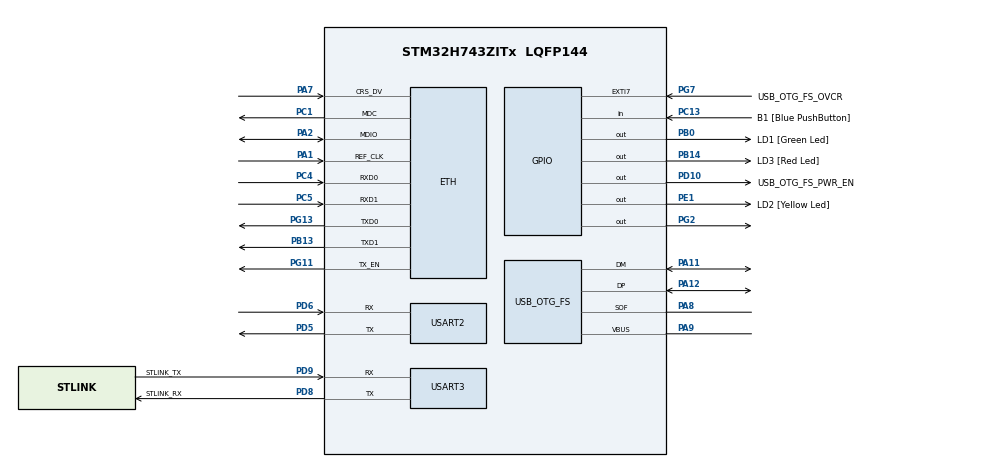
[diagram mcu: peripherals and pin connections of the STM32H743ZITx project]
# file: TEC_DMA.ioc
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Dma.Request0=USART2_RX
Dma.Request1=USART2_TX
Dma.USART2_RX.0.Direction=DMA_PERIPH_TO_MEMORY
Dma.USART2_RX.0.EventEnable=DISABLE
Dma.USART2_RX.0.FIFOMode=DMA_FIFOMODE_DISABLE
Dma.USART2_RX.0.Instance=DMA1_Stream0
Dma.USART2_RX.0.MemDataAlignment=DMA_MDATAALIGN_BYTE
Dma.USART2_RX.0.MemInc=DMA_MINC_ENABLE
Dma.USART2_RX.0.Mode=DMA_NORMAL
Dma.USART2_RX.0.PeriphDataAlignment=DMA_PDATAALIGN_BYTE
Dma.USART2_RX.0.PeriphInc=DMA_PINC_DISABLE
Dma.USART2_RX.0.Polarity=HAL_DMAMUX_REQ_GEN_RISING
Dma.USART2_RX.0.Priority=DMA_PRIORITY_LOW
Dma.USART2_RX.0.RequestNumber=1
Dma.USART2_RX.0.SignalID=NONE
Dma.USART2_RX.0.SyncEnable=DISABLE
Dma.USART2_RX.0.SyncPolarity=HAL_DMAMUX_SYNC_NO_EVENT
Dma.USART2_RX.0.SyncRequestNumber=1
Dma.USART2_RX.0.SyncSignalID=NONE
Dma.USART2_TX.1.Direction=DMA_MEMORY_TO_PERIPH
Dma.USART2_TX.1.EventEnable=DISABLE
Dma.USART2_TX.1.FIFOMode=DMA_FIFOMODE_DISABLE
Dma.USART2_TX.1.Instance=DMA1_Stream1
Dma.USART2_TX.1.MemDataAlignment=DMA_MDATAALIGN_BYTE
Dma.USART2_TX.1.MemInc=DMA_MINC_ENABLE
Dma.USART2_TX.1.Mode=DMA_NORMAL
Dma.USART2_TX.1.PeriphDataAlignment=DMA_PDATAALIGN_BYTE
Dma.USART2_TX.1.PeriphInc=DMA_PINC_DISABLE
Dma.USART2_TX.1.Polarity=HAL_DMAMUX_REQ_GEN_RISING
Dma.USART2_TX.1.Priority=DMA_PRIORITY_LOW
Dma.USART2_TX.1.RequestNumber=1
Dma.USART2_TX.1.SignalID=NONE
Dma.USART2_TX.1.SyncEnable=DISABLE
Dma.USART2_TX.1.SyncPolarity=HAL_DMAMUX_SYNC_NO_EVENT
Dma.USART2_TX.1.SyncRequestNumber=1
Dma.USART2_TX.1.SyncSignalID=NONE
ETH.MediaInterface=HAL_ETH_RMII_MODE
Mcu.Family=STM32H7
Mcu.Name=STM32H743ZITx
Mcu.Package=LQFP144
NVIC.DMA1_Stream0_IRQn=true\:0\:0\:false\:false\:true\:false\:true\:true
NVIC.DMA1_Stream1_IRQn=true\:0\:0\:false\:false\:true\:false\:true\:true
NVIC.PriorityGroup=NVIC_PRIORITYGROUP_4
NVIC.USART2_IRQn=true\:0\:0\:false\:false\:true\:true\:true\:true
PA1.Mode=RMII
PA1.Signal=ETH_REF_CLK
PA11.Mode=Device_Only
PA11.Signal=USB_OTG_FS_DM
PA12.Mode=Device_Only
PA12.Signal=USB_OTG_FS_DP
PA2.Mode=RMII
PA2.Signal=ETH_MDIO
PA7.Mode=RMII
PA7.Signal=ETH_CRS_DV
PA8.Mode=Activate_SOF_FS
PA8.Signal=USB_OTG_FS_SOF
PA9.Mode=Activate_VBUS
PA9.Signal=USB_OTG_FS_VBUS
PB0.GPIO_Label=LD1 [Green Led]
PB0.Signal=GPIO_Output
PB13.Mode=RMII
PB13.Signal=ETH_TXD1
PB14.GPIO_Label=LD3 [Red Led]
PB14.Signal=GPIO_Output
PC1.Mode=RMII
PC1.Signal=ETH_MDC
PC13.GPIO_Label=B1 [Blue PushButton]
PC13.Signal=GPIO_Input
PC14-OSC32_IN\ (OSC32_IN).Mode=LSE-External-Oscillator
PC14-OSC32_IN\ (OSC32_IN).Signal=RCC_OSC32_IN
PC15-OSC32_OUT\ (OSC32_OUT).Mode=LSE-External-Oscillator
PC15-OSC32_OUT\ (OSC32_OUT).Signal=RCC_OSC32_OUT
PC4.Mode=RMII
PC4.Signal=ETH_RXD0
PC5.Mode=RMII
PC5.Signal=ETH_RXD1
PD10.GPIO_Label=USB_OTG_FS_PWR_EN
PD10.Signal=GPIO_Output
PD5.Mode=Asynchronous
PD5.Signal=USART2_TX
PD6.Mode=Asynchronous
PD6.Signal=USART2_RX
PD8.GPIO_Label=STLINK_RX
PD8.Mode=Asynchronous
PD8.Signal=USART3_TX
PD9.GPIO_Label=STLINK_TX
PD9.Mode=Asynchronous
PD9.Signal=USART3_RX
PE1.GPIO_Label=LD2 [Yellow Led]
PE1.Signal=GPIO_Output
PG11.Mode=RMII
PG11.Signal=ETH_TX_EN
PG13.Mode=RMII
PG13.Signal=ETH_TXD0
PG2.Signal=GPIO_Output
PG7.GPIO_Label=USB_OTG_FS_OVCR
PG7.Signal=GPXTI7
PH0-OSC_IN\ (PH0).Mode=HSE-External-Clock-Source
PH0-OSC_IN\ (PH0).Signal=RCC_OSC_IN
PH1-OSC_OUT\ (PH1).Signal=RCC_OSC_OUT
ProjectManager.HeapSize=0x200
ProjectManager.StackSize=0x400
ProjectManager.TargetToolchain=STM32CubeIDE
RCC.ADCFreq_Value=16125000
RCC.APB1Freq_Value=100000000
RCC.APB2Freq_Value=100000000
RCC.APB3Freq_Value=100000000
RCC.APB4Freq_Value=100000000
RCC.CortexFreq_Value=400000000
RCC.D1PPRE=RCC_APB3_DIV2
RCC.D2PPRE1=RCC_APB1_DIV2
RCC.D2PPRE2=RCC_APB2_DIV2
RCC.D3PPRE=RCC_APB4_DIV2
RCC.DIVM1=1
RCC.DIVN1=100
RCC.DIVQ1=13
RCC.HCLKFreq_Value=200000000
RCC.HPRE=RCC_HCLK_DIV2
RCC.HSE_VALUE=8000000
RCC.PLL2FRACN=0
RCC.PLL3FRACN=0
RCC.PLLFRACN=0
RCC.PWR_Regulator_Voltage_Scale=PWR_REGULATOR_VOLTAGE_SCALE0
RCC.SYSCLKFreq_VALUE=400000000
RCC.SYSCLKSource=RCC_SYSCLKSOURCE_PLLCLK
RCC.USBFreq_Value=61538461.538461536
USART2.VirtualMode-Asynchronous=VM_ASYNC
USART3.VirtualMode-Asynchronous=VM_ASYNC
USB_OTG_FS.VirtualMode=Device_Only
board=NUCLEO-H743ZI2

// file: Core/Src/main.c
/* USER CODE BEGIN Header */
/**
  ******************************************************************************
  * @file           : main.c
  * @brief          : Main program body
  ******************************************************************************
  * @attention
  *
  * Copyright (c) 2024 STMicroelectronics.
  * All rights reserved.
  *
  * This software is licensed under terms that can be found in the LICENSE file
  * in the root directory of this software component.
  * If no LICENSE file comes with this software, it is provided AS-IS.
  *
  ******************************************************************************
  */
/* USER CODE END Header */
#include "main.h"
#include "string.h"

/* USER CODE BEGIN Includes */
#include "MTD1020T.h"
/* USER CODE END Includes */

#if defined ( __ICCARM__ ) /*!< IAR Compiler */
#pragma location=0x30000000
ETH_DMADescTypeDef  DMARxDscrTab[ETH_RX_DESC_CNT]; /* Ethernet Rx DMA Descriptors */
#pragma location=0x30000200
ETH_DMADescTypeDef  DMATxDscrTab[ETH_TX_DESC_CNT]; /* Ethernet Tx DMA Descriptors */

#elif defined ( __CC_ARM )  /* MDK ARM Compiler */

__attribute__((at(0x30000000))) ETH_DMADescTypeDef  DMARxDscrTab[ETH_RX_DESC_CNT]; /* Ethernet Rx DMA Descriptors */
__attribute__((at(0x30000200))) ETH_DMADescTypeDef  DMATxDscrTab[ETH_TX_DESC_CNT]; /* Ethernet Tx DMA Descriptors */

#elif defined ( __GNUC__ ) /* GNU Compiler */
ETH_DMADescTypeDef DMARxDscrTab[ETH_RX_DESC_CNT] __attribute__((section(".RxDecripSection"))); /* Ethernet Rx DMA Descriptors */
ETH_DMADescTypeDef DMATxDscrTab[ETH_TX_DESC_CNT] __attribute__((section(".TxDecripSection")));   /* Ethernet Tx DMA Descriptors */

#endif

ETH_TxPacketConfig TxConfig;

ETH_HandleTypeDef heth;

UART_HandleTypeDef huart2;
UART_HandleTypeDef huart3;
DMA_HandleTypeDef hdma_usart2_rx;
DMA_HandleTypeDef hdma_usart2_tx;

PCD_HandleTypeDef hpcd_USB_OTG_FS;

/* USER CODE BEGIN PV */

uint8_t rx[15];
uint8_t rx2[15];
/* USER CODE END PV */

void SystemClock_Config(void);
static void MX_GPIO_Init(void);
static void MX_DMA_Init(void);
static void MX_USART3_UART_Init(void);
static void MX_USB_OTG_FS_PCD_Init(void);
static void MX_USART2_UART_Init(void);
static void MX_ETH_Init(void);

int main(void)
{

  /* MCU Configuration--------------------------------------------------------*/

  /* Reset of all peripherals, Initializes the Flash interface and the Systick. */
  HAL_Init();

  /* Configure the system clock */
  SystemClock_Config();

  /* Initialize all configured peripherals */
  MX_GPIO_Init();
  MX_DMA_Init();
  MX_USART3_UART_Init();
  MX_USB_OTG_FS_PCD_Init();
  MX_USART2_UART_Init();
  MX_ETH_Init();
  /* USER CODE BEGIN 2 */
  MTD_Init();
 //TEC TEC;
  /* USER CODE END 2 */

  /* Infinite loop */
  /* USER CODE BEGIN WHILE */
  while (1)
  {
	//  HAL_UART_Transmit_DMA(&huart2, r_actual_T,4);
	  MTD_r_ActualTemp(rx2 );

	  //HAL_UARTEx_ReceiveToIdle_DMA(&huart2, rx, 10);

    /* USER CODE END WHILE */

  }
}

void SystemClock_Config(void)
{
  RCC_OscInitTypeDef RCC_OscInitStruct = {0};
  RCC_ClkInitTypeDef RCC_ClkInitStruct = {0};

  /** Supply configuration update enable
  */
  HAL_PWREx_ConfigSupply(PWR_LDO_SUPPLY);

  /** Configure the main internal regulator output voltage
  */
  __HAL_PWR_VOLTAGESCALING_CONFIG(PWR_REGULATOR_VOLTAGE_SCALE1);

  while(!__HAL_PWR_GET_FLAG(PWR_FLAG_VOSRDY)) {}

  __HAL_RCC_SYSCFG_CLK_ENABLE();
  __HAL_PWR_VOLTAGESCALING_CONFIG(PWR_REGULATOR_VOLTAGE_SCALE0);

  while(!__HAL_PWR_GET_FLAG(PWR_FLAG_VOSRDY)) {}

  /** Initializes the RCC Oscillators according to the specified parameters
  * in the RCC_OscInitTypeDef structure.
  */
  RCC_OscInitStruct.OscillatorType = RCC_OSCILLATORTYPE_HSE;
  RCC_OscInitStruct.HSEState = RCC_HSE_BYPASS;
  RCC_OscInitStruct.PLL.PLLState = RCC_PLL_ON;
  RCC_OscInitStruct.PLL.PLLSource = RCC_PLLSOURCE_HSE;
  RCC_OscInitStruct.PLL.PLLM = 1;
  RCC_OscInitStruct.PLL.PLLN = 100;
  RCC_OscInitStruct.PLL.PLLP = 2;
  RCC_OscInitStruct.PLL.PLLQ = 13;
  RCC_OscInitStruct.PLL.PLLR = 2;
  RCC_OscInitStruct.PLL.PLLRGE = RCC_PLL1VCIRANGE_3;
  RCC_OscInitStruct.PLL.PLLVCOSEL = RCC_PLL1VCOWIDE;
  RCC_OscInitStruct.PLL.PLLFRACN = 0;
  if (HAL_RCC_OscConfig(&RCC_OscInitStruct) != HAL_OK)
  {
    Error_Handler();
  }

  /** Initializes the CPU, AHB and APB buses clocks
  */
  RCC_ClkInitStruct.ClockType = RCC_CLOCKTYPE_HCLK|RCC_CLOCKTYPE_SYSCLK
                              |RCC_CLOCKTYPE_PCLK1|RCC_CLOCKTYPE_PCLK2
                              |RCC_CLOCKTYPE_D3PCLK1|RCC_CLOCKTYPE_D1PCLK1;
  RCC_ClkInitStruct.SYSCLKSource = RCC_SYSCLKSOURCE_PLLCLK;
  RCC_ClkInitStruct.SYSCLKDivider = RCC_SYSCLK_DIV1;
  RCC_ClkInitStruct.AHBCLKDivider = RCC_HCLK_DIV2;
  RCC_ClkInitStruct.APB3CLKDivider = RCC_APB3_DIV2;
  RCC_ClkInitStruct.APB1CLKDivider = RCC_APB1_DIV2;
  RCC_ClkInitStruct.APB2CLKDivider = RCC_APB2_DIV2;
  RCC_ClkInitStruct.APB4CLKDivider = RCC_APB4_DIV2;

  if (HAL_RCC_ClockConfig(&RCC_ClkInitStruct, FLASH_LATENCY_2) != HAL_OK)
  {
    Error_Handler();
  }
}

static void MX_ETH_Init(void)
{

   static uint8_t MACAddr[6];

  heth.Instance = ETH;
  MACAddr[0] = 0x00;
  MACAddr[1] = 0x80;
  MACAddr[2] = 0xE1;
  MACAddr[3] = 0x00;
  MACAddr[4] = 0x00;
  MACAddr[5] = 0x00;
  heth.Init.MACAddr = &MACAddr[0];
  heth.Init.MediaInterface = HAL_ETH_RMII_MODE;
  heth.Init.TxDesc = DMATxDscrTab;
  heth.Init.RxDesc = DMARxDscrTab;
  heth.Init.RxBuffLen = 1524;

  if (HAL_ETH_Init(&heth) != HAL_OK)
  {
    Error_Handler();
  }

  memset(&TxConfig, 0 , sizeof(ETH_TxPacketConfig));
  TxConfig.Attributes = ETH_TX_PACKETS_FEATURES_CSUM | ETH_TX_PACKETS_FEATURES_CRCPAD;
  TxConfig.ChecksumCtrl = ETH_CHECKSUM_IPHDR_PAYLOAD_INSERT_PHDR_CALC;
  TxConfig.CRCPadCtrl = ETH_CRC_PAD_INSERT;

}

static void MX_USART2_UART_Init(void)
{

  huart2.Instance = USART2;
  huart2.Init.BaudRate = 115200;
  huart2.Init.WordLength = UART_WORDLENGTH_8B;
  huart2.Init.StopBits = UART_STOPBITS_1;
  huart2.Init.Parity = UART_PARITY_NONE;
  huart2.Init.Mode = UART_MODE_TX_RX;
  huart2.Init.HwFlowCtl = UART_HWCONTROL_NONE;
  huart2.Init.OverSampling = UART_OVERSAMPLING_16;
  huart2.Init.OneBitSampling = UART_ONE_BIT_SAMPLE_DISABLE;
  huart2.Init.ClockPrescaler = UART_PRESCALER_DIV1;
  huart2.AdvancedInit.AdvFeatureInit = UART_ADVFEATURE_NO_INIT;
  if (HAL_UART_Init(&huart2) != HAL_OK)
  {
    Error_Handler();
  }
  if (HAL_UARTEx_SetTxFifoThreshold(&huart2, UART_TXFIFO_THRESHOLD_1_8) != HAL_OK)
  {
    Error_Handler();
  }
  if (HAL_UARTEx_SetRxFifoThreshold(&huart2, UART_RXFIFO_THRESHOLD_1_8) != HAL_OK)
  {
    Error_Handler();
  }
  if (HAL_UARTEx_DisableFifoMode(&huart2) != HAL_OK)
  {
    Error_Handler();
  }

}

static void MX_USART3_UART_Init(void)
{

  huart3.Instance = USART3;
  huart3.Init.BaudRate = 115200;
  huart3.Init.WordLength = UART_WORDLENGTH_8B;
  huart3.Init.StopBits = UART_STOPBITS_1;
  huart3.Init.Parity = UART_PARITY_NONE;
  huart3.Init.Mode = UART_MODE_TX_RX;
  huart3.Init.HwFlowCtl = UART_HWCONTROL_NONE;
  huart3.Init.OverSampling = UART_OVERSAMPLING_16;
  huart3.Init.OneBitSampling = UART_ONE_BIT_SAMPLE_DISABLE;
  huart3.Init.ClockPrescaler = UART_PRESCALER_DIV1;
  huart3.AdvancedInit.AdvFeatureInit = UART_ADVFEATURE_NO_INIT;
  if (HAL_UART_Init(&huart3) != HAL_OK)
  {
    Error_Handler();
  }
  if (HAL_UARTEx_SetTxFifoThreshold(&huart3, UART_TXFIFO_THRESHOLD_1_8) != HAL_OK)
  {
    Error_Handler();
  }
  if (HAL_UARTEx_SetRxFifoThreshold(&huart3, UART_RXFIFO_THRESHOLD_1_8) != HAL_OK)
  {
    Error_Handler();
  }
  if (HAL_UARTEx_DisableFifoMode(&huart3) != HAL_OK)
  {
    Error_Handler();
  }

}

static void MX_USB_OTG_FS_PCD_Init(void)
{

  hpcd_USB_OTG_FS.Instance = USB_OTG_FS;
  hpcd_USB_OTG_FS.Init.dev_endpoints = 9;
  hpcd_USB_OTG_FS.Init.speed = PCD_SPEED_FULL;
  hpcd_USB_OTG_FS.Init.dma_enable = DISABLE;
  hpcd_USB_OTG_FS.Init.phy_itface = PCD_PHY_EMBEDDED;
  hpcd_USB_OTG_FS.Init.Sof_enable = ENABLE;
  hpcd_USB_OTG_FS.Init.low_power_enable = DISABLE;
  hpcd_USB_OTG_FS.Init.lpm_enable = DISABLE;
  hpcd_USB_OTG_FS.Init.battery_charging_enable = ENABLE;
  hpcd_USB_OTG_FS.Init.vbus_sensing_enable = ENABLE;
  hpcd_USB_OTG_FS.Init.use_dedicated_ep1 = DISABLE;
  if (HAL_PCD_Init(&hpcd_USB_OTG_FS) != HAL_OK)
  {
    Error_Handler();
  }

}

static void MX_DMA_Init(void)
{

  /* DMA controller clock enable */
  __HAL_RCC_DMA1_CLK_ENABLE();

  /* DMA interrupt init */
  /* DMA1_Stream0_IRQn interrupt configuration */
  HAL_NVIC_SetPriority(DMA1_Stream0_IRQn, 0, 0);
  HAL_NVIC_EnableIRQ(DMA1_Stream0_IRQn);
  /* DMA1_Stream1_IRQn interrupt configuration */
  HAL_NVIC_SetPriority(DMA1_Stream1_IRQn, 0, 0);
  HAL_NVIC_EnableIRQ(DMA1_Stream1_IRQn);

}

static void MX_GPIO_Init(void)
{
  GPIO_InitTypeDef GPIO_InitStruct = {0};

  /* GPIO Ports Clock Enable */
  __HAL_RCC_GPIOC_CLK_ENABLE();
  __HAL_RCC_GPIOH_CLK_ENABLE();
  __HAL_RCC_GPIOA_CLK_ENABLE();
  __HAL_RCC_GPIOB_CLK_ENABLE();
  __HAL_RCC_GPIOD_CLK_ENABLE();
  __HAL_RCC_GPIOG_CLK_ENABLE();
  __HAL_RCC_GPIOE_CLK_ENABLE();

  /*Configure GPIO pin Output Level */
  HAL_GPIO_WritePin(GPIOB, LD1_Pin|LD3_Pin, GPIO_PIN_RESET);

  /*Configure GPIO pin Output Level */
  HAL_GPIO_WritePin(USB_OTG_FS_PWR_EN_GPIO_Port, USB_OTG_FS_PWR_EN_Pin, GPIO_PIN_RESET);

  /*Configure GPIO pin Output Level */
  HAL_GPIO_WritePin(GPIOG, GPIO_PIN_2, GPIO_PIN_RESET);

  /*Configure GPIO pin Output Level */
  HAL_GPIO_WritePin(LD2_GPIO_Port, LD2_Pin, GPIO_PIN_RESET);

  /*Configure GPIO pin : B1_Pin */
  GPIO_InitStruct.Pin = B1_Pin;
  GPIO_InitStruct.Mode = GPIO_MODE_INPUT;
  GPIO_InitStruct.Pull = GPIO_NOPULL;
  HAL_GPIO_Init(B1_GPIO_Port, &GPIO_InitStruct);

  /*Configure GPIO pins : LD1_Pin LD3_Pin */
  GPIO_InitStruct.Pin = LD1_Pin|LD3_Pin;
  GPIO_InitStruct.Mode = GPIO_MODE_OUTPUT_PP;
  GPIO_InitStruct.Pull = GPIO_NOPULL;
  GPIO_InitStruct.Speed = GPIO_SPEED_FREQ_LOW;
  HAL_GPIO_Init(GPIOB, &GPIO_InitStruct);

  /*Configure GPIO pin : USB_OTG_FS_PWR_EN_Pin */
  GPIO_InitStruct.Pin = USB_OTG_FS_PWR_EN_Pin;
  GPIO_InitStruct.Mode = GPIO_MODE_OUTPUT_PP;
  GPIO_InitStruct.Pull = GPIO_NOPULL;
  GPIO_InitStruct.Speed = GPIO_SPEED_FREQ_LOW;
  HAL_GPIO_Init(USB_OTG_FS_PWR_EN_GPIO_Port, &GPIO_InitStruct);

  /*Configure GPIO pin : PG2 */
  GPIO_InitStruct.Pin = GPIO_PIN_2;
  GPIO_InitStruct.Mode = GPIO_MODE_OUTPUT_PP;
  GPIO_InitStruct.Pull = GPIO_NOPULL;
  GPIO_InitStruct.Speed = GPIO_SPEED_FREQ_LOW;
  HAL_GPIO_Init(GPIOG, &GPIO_InitStruct);

  /*Configure GPIO pin : USB_OTG_FS_OVCR_Pin */
  GPIO_InitStruct.Pin = USB_OTG_FS_OVCR_Pin;
  GPIO_InitStruct.Mode = GPIO_MODE_IT_RISING;
  GPIO_InitStruct.Pull = GPIO_NOPULL;
  HAL_GPIO_Init(USB_OTG_FS_OVCR_GPIO_Port, &GPIO_InitStruct);

  /*Configure GPIO pin : LD2_Pin */
  GPIO_InitStruct.Pin = LD2_Pin;
  GPIO_InitStruct.Mode = GPIO_MODE_OUTPUT_PP;
  GPIO_InitStruct.Pull = GPIO_NOPULL;
  GPIO_InitStruct.Speed = GPIO_SPEED_FREQ_LOW;
  HAL_GPIO_Init(LD2_GPIO_Port, &GPIO_InitStruct);

}

void Error_Handler(void)
{
  __disable_irq();
  while (1)
  {
  }
}
